AUTOSAR XML (schema 4.0)
package /Powertrain_Components
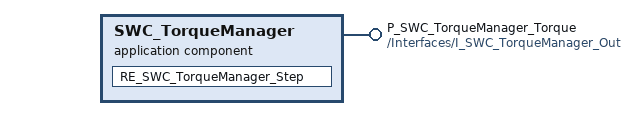
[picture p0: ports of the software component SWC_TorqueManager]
  application sw component type SWC_TorqueManager  # AUTOSAR Application SWC SWC_TorqueManager for Powertrain Control
    provide port P_SWC_TorqueManager_Torque: provided-interface=/Interfaces/I_SWC_TorqueManager_Out
    behavior SWC_TorqueManager_Behavior
      runnable RE_SWC_TorqueManager_Step: symbol=SWC_TorqueManager_Step
  sender receiver interface I_SWC_TorqueManager_Out
    data DE_SWC_TorqueManager_TorqueDemand: type=/AUTOSAR/Platform/uint32
